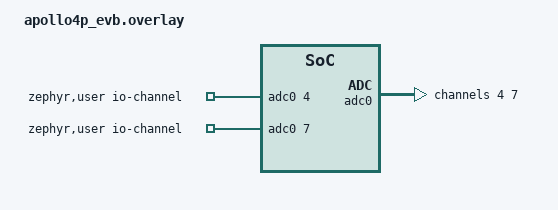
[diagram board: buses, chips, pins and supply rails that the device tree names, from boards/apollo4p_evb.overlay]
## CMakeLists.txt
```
# SPDX-License-Identifier: Apache-2.0

cmake_minimum_required(VERSION 3.20.0)

find_package(Zephyr HINTS $ENV{ZEPHYR_BASE})
project(ADC)

target_sources(app PRIVATE src/main.c)
```

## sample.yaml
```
sample:
  name: ADC driver sample
tests:
  sample.drivers.adc:
    tags:
      - adc
    depends_on: adc
    platform_allow:
      - nucleo_l073rz
      - disco_l475_iot1
      - cc3220sf_launchxl
      - cc3235sf_launchxl
      - cy8cproto_063_ble
      - stm32l496g_disco
      - stm32h735g_disco
      - nrf51dk/nrf51822
      - nrf52840dk/nrf52840
      - mec172xevb_assy6906
      - gd32f350r_eval
      - gd32f450i_eval
      - gd32vf103v_eval
      - gd32f403z_eval
      - esp32_devkitc_wroom/esp32/procpu
      - esp32_devkitc_wrover/esp32/procpu
      - esp32s2_saola
      - esp32c3_devkitm
      - gd32l233r_eval
      - lpcxpresso55s36
      - mr_canhubk3
      - longan_nano
      - longan_nano/gd32vf103/lite
      - rd_rw612_bga
    integration_platforms:
      - nucleo_l073rz
      - nrf52840dk/nrf52840
    harness: console
    timeout: 10
    harness_config:
      type: multi_line
      regex:
        - "ADC reading\\[\\d+\\]:"
        - "- .+, channel \\d+: -?\\d+"
```

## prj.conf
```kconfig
CONFIG_ADC=y
CONFIG_ADC_ESP32=y

CONFIG_LOG=y
CONFIG_LOG_MODE_MINIMAL=y
CONFIG_ADC_LOG_LEVEL_DBG=y
```

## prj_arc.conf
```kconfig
CONFIG_ADC=y
CONFIG_ADC_DW=y
CONFIG_ADC_DW_REPETITIVE=y
```

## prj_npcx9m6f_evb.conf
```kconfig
CONFIG_ADC_CMP_NPCX=y
CONFIG_SENSOR=y
CONFIG_SENSOR_SHELL=n
CONFIG_TACH_NPCX=n
# Uncomment line below to test optimization
CONFIG_NO_OPTIMIZATIONS=y
```

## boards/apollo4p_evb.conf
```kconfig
CONFIG_STDOUT_CONSOLE=y
CONFIG_NO_OPTIMIZATIONS=y
CONFIG_MAIN_STACK_SIZE=4096
CONFIG_IDLE_STACK_SIZE=4096
CONFIG_PM=y
```

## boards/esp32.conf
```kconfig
#CONFIG_SHELL=y
#CONFIG_LOG=y
#CONFIG_ADC_ESP32=y

#CONFIG_LOG_MODE_DEFERRED=y
#CONFIG_LOG_MODE_MINIMAL=y
#CONFIG_ADC_LOG_LEVEL_DBG=y
```

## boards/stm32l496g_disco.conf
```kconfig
# Copyright (c) 2021 STMicroelectronics
# SPDX-License-Identifier: Apache-2.0

CONFIG_LOG=y
```

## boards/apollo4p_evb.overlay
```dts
/*
 * Copyright (c) 2024 Ambiq Micro Inc.
 *
 * SPDX-License-Identifier: Apache-2.0
 */
/ {
	zephyr,user {
		io-channels = <&adc0 4>, <&adc0 7>;
	};
};

&adc0 {
	status = "okay";
	interrupt-parent = <&nvic>;
	interrupts = <19 0>;
	#address-cells = <1>;
	#size-cells = <0>;

	channel@4 {
		reg = <4>;
		zephyr,gain = "ADC_GAIN_1";
		zephyr,reference = "ADC_REF_INTERNAL";
		zephyr,acquisition-time = <ADC_ACQ_TIME_DEFAULT>;
		zephyr,resolution = <12>;
	};

	channel@7 {
		reg = <7>;
		zephyr,gain = "ADC_GAIN_1";
		zephyr,reference = "ADC_REF_INTERNAL";
		zephyr,acquisition-time = <ADC_ACQ_TIME_DEFAULT>;
		zephyr,resolution = <12>;
	};
};
```

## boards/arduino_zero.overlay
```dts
/*
 * SPDX-License-Identifier: Apache-2.0
 *
 * Copyright (c) 2022 Kim Bøndergaard <kim@fam-boendergaard.dk>
 */

/ {
	zephyr,user {
		/* J106.6 (A5) aka D21G18, pin PB02_AIN10 */
		io-channels = <&adc 10>;
	};
};

&adc {
	status = "okay";
};
```

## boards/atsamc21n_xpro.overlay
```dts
/*
 * SPDX-License-Identifier: Apache-2.0
 *
 * Copyright (c) 2021 Argentum Systems Ltd.
 */

#include <zephyr/dt-bindings/adc/adc.h>

/ {
	zephyr,user {
		/* EXT-1, pin 3 ADC(+) */
		io-channels = <&adc0 3>;
	};
};

&adc0 {
	#address-cells = <1>;
	#size-cells = <0>;

	channel@3 {
		reg = <3>;
		zephyr,gain = "ADC_GAIN_1";
		zephyr,reference = "ADC_REF_INTERNAL";
		zephyr,acquisition-time = <ADC_ACQ_TIME_DEFAULT>;
		zephyr,resolution = <12>;
		zephyr,input-positive = <3>;
	};
};
```

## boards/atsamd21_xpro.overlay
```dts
/*
 * SPDX-License-Identifier: Apache-2.0
 *
 * Copyright (c) 2021 Argentum Systems Ltd.
 */

#include <zephyr/dt-bindings/adc/adc.h>

/ {
	zephyr,user {
		/* EXT-1, pin 3 ADC(+) */
		io-channels = <&adc 8>;
	};
};

&adc {
	#address-cells = <1>;
	#size-cells = <0>;

	channel@8 {
		reg = <8>;
		zephyr,gain = "ADC_GAIN_1";
		zephyr,reference = "ADC_REF_INTERNAL";
		zephyr,acquisition-time = <ADC_ACQ_TIME_DEFAULT>;
		zephyr,resolution = <12>;
		zephyr,input-positive = <8>;
	};
};
```

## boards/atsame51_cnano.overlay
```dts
/*
 * SPDX-License-Identifier: Apache-2.0
 *
 * Copyright (c) 2021 Gerson Fernando Budke <nandojve@gmail.com>
 */

 / {
	zephyr,user {
		/* EXT-1 ADC(+) */
		io-channels = <&adc0 15>;
	};
};

&adc0 {
	#address-cells = <1>;
	#size-cells = <0>;

	channel@15 {
		reg = <15>;
		zephyr,gain = "ADC_GAIN_1";
		zephyr,reference = "ADC_REF_INTERNAL";
		zephyr,acquisition-time = <ADC_ACQ_TIME_DEFAULT>;
		zephyr,resolution = <12>;
		zephyr,input-positive = <15>;
	};
};
```

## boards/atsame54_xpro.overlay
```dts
/*
 * SPDX-License-Identifier: Apache-2.0
 *
 * Copyright (c) 2021 Gerson Fernando Budke <nandojve@gmail.com>
 */

#include <zephyr/dt-bindings/adc/adc.h>

/ {
	zephyr,user {
		/* EXT-1 ADC(+) */
		io-channels = <&adc1 6>;
	};
};

&adc1 {
	#address-cells = <1>;
	#size-cells = <0>;

	channel@6 {
		reg = <6>;
		zephyr,gain = "ADC_GAIN_1";
		zephyr,reference = "ADC_REF_INTERNAL";
		zephyr,acquisition-time = <ADC_ACQ_TIME_DEFAULT>;
		zephyr,resolution = <12>;
		zephyr,input-positive = <6>;
	};
};
```

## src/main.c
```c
/*
 * Copyright (c) 2020 Libre Solar Technologies GmbH
 *
 * SPDX-License-Identifier: Apache-2.0
 */

#include <inttypes.h>
#include <stddef.h>
#include <stdint.h>

#include <zephyr/device.h>
#include <zephyr/devicetree.h>
#include <zephyr/drivers/adc.h>
#include <zephyr/kernel.h>
#include <zephyr/sys/printk.h>
#include <zephyr/sys/util.h>

#if !DT_NODE_EXISTS(DT_PATH(zephyr_user)) || \
	!DT_NODE_HAS_PROP(DT_PATH(zephyr_user), io_channels)
#error "No suitable devicetree overlay specified"
#endif

#define DT_SPEC_AND_COMMA(node_id, prop, idx) \
	ADC_DT_SPEC_GET_BY_IDX(node_id, idx),

/* Data of ADC io-channels specified in devicetree. */
static const struct adc_dt_spec adc_channels[] = {
	DT_FOREACH_PROP_ELEM(DT_PATH(zephyr_user), io_channels,
			     DT_SPEC_AND_COMMA)
};

int main(void)
{
	int err;
	uint32_t count = 0;
	uint16_t buf;
	struct adc_sequence sequence = {
		.buffer = &buf,
		/* buffer size in bytes, not number of samples */
		.buffer_size = sizeof(buf),
	};

	/* Configure channels individually prior to sampling. */
	for (size_t i = 0U; i < ARRAY_SIZE(adc_channels); i++) {
		if (!adc_is_ready_dt(&adc_channels[i])) {
			printk("ADC controller device %s not ready\n", adc_channels[i].dev->name);
			return 0;
		}

		err = adc_channel_setup_dt(&adc_channels[i]);
		if (err < 0) {
			printk("Could not setup channel #%d (%d)\n", i, err);
			return 0;
		}
	}

	while (1) {
		printk("ADC reading[%u]:\n", count++);
		for (size_t i = 0U; i < ARRAY_SIZE(adc_channels); i++) {
			int32_t val_mv;

			printk("- %s, channel %d: ",
			       adc_channels[i].dev->name,
			       adc_channels[i].channel_id);

			(void)adc_sequence_init_dt(&adc_channels[i], &sequence);

			err = adc_read_dt(&adc_channels[i], &sequence);
			if (err < 0) {
				printk("Could not read (%d)\n", err);
				continue;
			}

			/*
			 * If using differential mode, the 16 bit value
			 * in the ADC sample buffer should be a signed 2's
			 * complement value.
			 */
			if (adc_channels[i].channel_cfg.differential) {
				val_mv = (int32_t)((int16_t)buf);
			} else {
				val_mv = (int32_t)buf;
			}
			printk("%"PRId32, val_mv);
			err = adc_raw_to_millivolts_dt(&adc_channels[i],
						       &val_mv);
			/* conversion to mV may not be supported, skip if not */
			if (err < 0) {
				printk(" (value in mV not available)\n");
			} else {
				printk(" = %"PRId32" mV\n", val_mv);
			}
		}

		k_sleep(K_MSEC(1000));
	}
	return 0;
}
```

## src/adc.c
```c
/* adc.c - ADC test source file */

/*
 * Copyright (c) 2015 Intel Corporation.
 *
 * Licensed under the Apache License, Version 2.0 (the "License");
 * you may not use this file except in compliance with the License.
 * You may obtain a copy of the License at
 *
 *     http://www.apache.org/licenses/LICENSE-2.0
 *
 * Unless required by applicable law or agreed to in writing, software
 * distributed under the License is distributed on an "AS IS" BASIS,
 * WITHOUT WARRANTIES OR CONDITIONS OF ANY KIND, either express or implied.
 * See the License for the specific language governing permissions and
 * limitations under the License.
 */

#include <zephyr.h>

#include <device.h>
#include <misc/byteorder.h>
#define SYS_LOG_NO_NEWLINE
#include <misc/sys_log.h>
#include <adc.h>

#define SLEEPTIME  2
#define SLEEPTICKS (SLEEPTIME * sys_clock_ticks_per_sec)

#define ADC_DEVICE_NAME "ADC_0"

/*
 * The analog input pin and channel number mapping
 * for Arduino 101 board.
 * A0 Channel 10
 * A1 Channel 11
 * A2 Channel 12
 * A3 Channel 13
 * A4 Channel 14
 */
#define CHANNEL 10
#define BUFFER_SIZE 40

static uint8_t seq_buffer[BUFFER_SIZE];

static struct adc_seq_entry sample = {
	.sampling_delay = 12,
	.channel_id = CHANNEL,
	.buffer = seq_buffer,
	.buffer_length = BUFFER_SIZE,
};

static struct adc_seq_table table = {
	.entries = &sample,
	.num_entries = 1,
};

static void _print_sample_in_hex(uint8_t *buf, uint32_t length)
{
	SYS_LOG_DBG("Buffer content:\n");
	for (; length > 0; length -= 4, buf += 4) {
		SYS_LOG_DBG("0x%x ", *((uint32_t *)buf));
	}
	SYS_LOG_DBG("\n");
}

void main(void)
{
	struct device *adc;
	struct nano_timer timer;
	uint32_t data[2] = {0, 0};

	SYS_LOG_DBG("ADC sample started on %s\n", ADC_DEVICE_NAME);

	adc = device_get_binding(ADC_DEVICE_NAME);
	if (!adc) {
		SYS_LOG_DBG("Cannot get adc controller\n");
		return;
	}

	nano_timer_init(&timer, data);
	adc_enable(adc);
	while (1) {
		if (adc_read(adc, &table) != 0) {
			SYS_LOG_DBG("Sampling could not proceed, an error occurred\n");
		} else {
			SYS_LOG_DBG("Sampling is done\n");
			_print_sample_in_hex(seq_buffer, BUFFER_SIZE);
		}
		nano_timer_start(&timer, SLEEPTICKS);
		nano_timer_test(&timer, TICKS_UNLIMITED);
	}
	adc_disable(adc);
}
```
